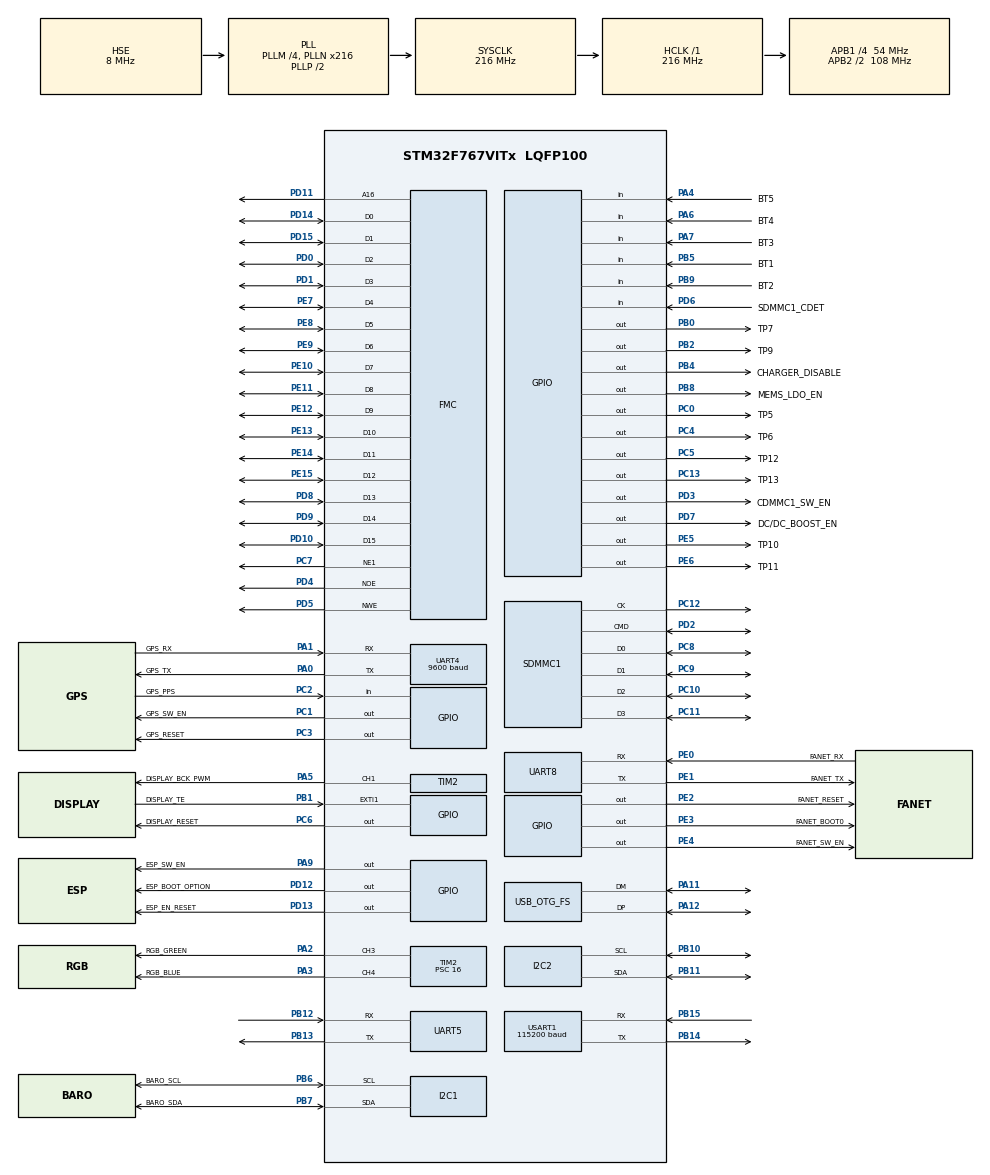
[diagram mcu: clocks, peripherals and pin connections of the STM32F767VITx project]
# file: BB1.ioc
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CORTEX_M7.ART_ACCLERATOR_ENABLE=0
CORTEX_M7.CPU_DCache=Disabled
CORTEX_M7.CPU_ICache=Disabled
CORTEX_M7.FlashInterface=AXI_Enabled
CORTEX_M7.PREFETCH_ENABLE=0
DMA2D.AlphaModeBackground=DMA2D_REPLACE_ALPHA
DMA2D.AlphaModeForeground=DMA2D_REPLACE_ALPHA
DMA2D.ColorMode=DMA2D_OUTPUT_RGB565
DMA2D.InputAlphaBackground=0xff
DMA2D.InputAlphaForeground=0xff
DMA2D.InputColorModeBackground=DMA2D_INPUT_RGB565
DMA2D.InputColorModeForeground=DMA2D_INPUT_RGB565
DMA2D.Mode=DMA2D_M2M_BLEND
Dma.MEMTOMEM.0.Direction=DMA_MEMORY_TO_MEMORY
Dma.MEMTOMEM.0.FIFOMode=DMA_FIFOMODE_ENABLE
Dma.MEMTOMEM.0.FIFOThreshold=DMA_FIFO_THRESHOLD_FULL
Dma.MEMTOMEM.0.Instance=DMA2_Stream0
Dma.MEMTOMEM.0.MemBurst=DMA_MBURST_SINGLE
Dma.MEMTOMEM.0.MemDataAlignment=DMA_MDATAALIGN_WORD
Dma.MEMTOMEM.0.MemInc=DMA_MINC_DISABLE
Dma.MEMTOMEM.0.Mode=DMA_NORMAL
Dma.MEMTOMEM.0.PeriphBurst=DMA_PBURST_SINGLE
Dma.MEMTOMEM.0.PeriphDataAlignment=DMA_PDATAALIGN_WORD
Dma.MEMTOMEM.0.PeriphInc=DMA_PINC_ENABLE
Dma.MEMTOMEM.0.Priority=DMA_PRIORITY_LOW
Dma.Request0=MEMTOMEM
Dma.Request1=SDMMC1_RX
Dma.Request2=SDMMC1_TX
Dma.Request3=UART4_RX
Dma.Request4=UART8_RX
Dma.Request5=USART1_TX
Dma.SDMMC1_RX.1.Direction=DMA_PERIPH_TO_MEMORY
Dma.SDMMC1_RX.1.FIFOMode=DMA_FIFOMODE_ENABLE
Dma.SDMMC1_RX.1.FIFOThreshold=DMA_FIFO_THRESHOLD_FULL
Dma.SDMMC1_RX.1.Instance=DMA2_Stream3
Dma.SDMMC1_RX.1.MemBurst=DMA_MBURST_INC4
Dma.SDMMC1_RX.1.MemDataAlignment=DMA_MDATAALIGN_WORD
Dma.SDMMC1_RX.1.MemInc=DMA_MINC_ENABLE
Dma.SDMMC1_RX.1.Mode=DMA_PFCTRL
Dma.SDMMC1_RX.1.PeriphBurst=DMA_PBURST_INC4
Dma.SDMMC1_RX.1.PeriphDataAlignment=DMA_PDATAALIGN_WORD
Dma.SDMMC1_RX.1.PeriphInc=DMA_PINC_DISABLE
Dma.SDMMC1_RX.1.Priority=DMA_PRIORITY_MEDIUM
Dma.SDMMC1_TX.2.Direction=DMA_MEMORY_TO_PERIPH
Dma.SDMMC1_TX.2.FIFOMode=DMA_FIFOMODE_ENABLE
Dma.SDMMC1_TX.2.FIFOThreshold=DMA_FIFO_THRESHOLD_FULL
Dma.SDMMC1_TX.2.Instance=DMA2_Stream6
Dma.SDMMC1_TX.2.MemBurst=DMA_MBURST_INC4
Dma.SDMMC1_TX.2.MemDataAlignment=DMA_MDATAALIGN_WORD
Dma.SDMMC1_TX.2.MemInc=DMA_MINC_ENABLE
Dma.SDMMC1_TX.2.Mode=DMA_PFCTRL
Dma.SDMMC1_TX.2.PeriphBurst=DMA_PBURST_INC4
Dma.SDMMC1_TX.2.PeriphDataAlignment=DMA_PDATAALIGN_WORD
Dma.SDMMC1_TX.2.PeriphInc=DMA_PINC_DISABLE
Dma.SDMMC1_TX.2.Priority=DMA_PRIORITY_MEDIUM
Dma.UART4_RX.3.Direction=DMA_PERIPH_TO_MEMORY
Dma.UART4_RX.3.FIFOMode=DMA_FIFOMODE_DISABLE
Dma.UART4_RX.3.Instance=DMA1_Stream2
Dma.UART4_RX.3.MemDataAlignment=DMA_MDATAALIGN_BYTE
Dma.UART4_RX.3.MemInc=DMA_MINC_ENABLE
Dma.UART4_RX.3.Mode=DMA_CIRCULAR
Dma.UART4_RX.3.PeriphDataAlignment=DMA_PDATAALIGN_BYTE
Dma.UART4_RX.3.PeriphInc=DMA_PINC_DISABLE
Dma.UART4_RX.3.Priority=DMA_PRIORITY_LOW
Dma.UART8_RX.4.Direction=DMA_PERIPH_TO_MEMORY
Dma.UART8_RX.4.FIFOMode=DMA_FIFOMODE_DISABLE
Dma.UART8_RX.4.Instance=DMA1_Stream6
Dma.UART8_RX.4.MemDataAlignment=DMA_MDATAALIGN_BYTE
Dma.UART8_RX.4.MemInc=DMA_MINC_ENABLE
Dma.UART8_RX.4.Mode=DMA_CIRCULAR
Dma.UART8_RX.4.PeriphDataAlignment=DMA_PDATAALIGN_BYTE
Dma.UART8_RX.4.PeriphInc=DMA_PINC_DISABLE
Dma.UART8_RX.4.Priority=DMA_PRIORITY_LOW
Dma.USART1_TX.5.Direction=DMA_MEMORY_TO_PERIPH
Dma.USART1_TX.5.FIFOMode=DMA_FIFOMODE_DISABLE
Dma.USART1_TX.5.Instance=DMA2_Stream7
Dma.USART1_TX.5.MemDataAlignment=DMA_MDATAALIGN_BYTE
Dma.USART1_TX.5.MemInc=DMA_MINC_ENABLE
Dma.USART1_TX.5.Mode=DMA_NORMAL
Dma.USART1_TX.5.PeriphDataAlignment=DMA_PDATAALIGN_BYTE
Dma.USART1_TX.5.PeriphInc=DMA_PINC_DISABLE
Dma.USART1_TX.5.Priority=DMA_PRIORITY_MEDIUM
FATFS.BSP.number=1
FATFS._FS_LOCK=20
FATFS._MAX_SS=512
FATFS._USE_MUTEX=1
FATFS0.BSP.STBoard=false
FATFS0.BSP.api=Unknown
FATFS0.BSP.i2caddr=0
FATFS0.BSP.instance=PD6
FATFS0.BSP.ip=GPIO
FATFS0.BSP.mode=Input
FATFS0.BSP.name=Detect_SDIO
FATFS0.BSP.solution=PD6
FMC.AddressSetupTime1=6
FMC.BusTurnAroundDuration1=0
FMC.DataSetupTime1=9
FMC.ExtendedMode1=FMC_EXTENDED_MODE_DISABLE
FMC.MemoryType1=FMC_MEMORY_TYPE_SRAM
FMC.WriteFifo1=FMC_WRITE_FIFO_ENABLE
FREERTOS.HEAP_NUMBER=4
FREERTOS.INCLUDE_vTaskDelete=0
FREERTOS.Queues01=queue_Debug,16,debug_msg_t,0,Static,queueDebugBuffer,queueDebugControlBlock
FREERTOS.Tasks01=System,24,1024,task_System,As weak,NULL,Static,defaultTaskBuffer,defaultTaskControlBlock;GUI,8,1024,task_GUI,As external,NULL,Static,GUIBuffer,GUIControlBlock;Debug,40,512,task_Debug,As external,NULL,Static,DebugBuffer,DebugControlBlock;Test,8,1024,task_Test,As external,NULL,Static,TestBuffer,TestControlBlock;GNSS,8,1024,task_GNSS,As external,NULL,Static,GNSSBuffer,GNSSControlBlock
FREERTOS.configENABLE_BACKWARD_COMPATIBILITY=1
FREERTOS.configENABLE_FPU=1
FREERTOS.configGENERATE_RUN_TIME_STATS=1
FREERTOS.configRECORD_STACK_HIGH_ADDRESS=1
FREERTOS.configUSE_APPLICATION_TASK_TAG=0
FREERTOS.configUSE_NEWLIB_REENTRANT=1
FREERTOS.configUSE_STATS_FORMATTING_FUNCTIONS=1
I2C1.Timing=0x20404768
I2C2.Timing=0x20404768
Mcu.Family=STM32F7
Mcu.Name=STM32F767VITx
Mcu.Package=LQFP100
NVIC.DMA1_Stream2_IRQn=true\:5\:0\:false\:false\:true\:true\:false\:true
NVIC.DMA1_Stream6_IRQn=true\:5\:0\:false\:false\:true\:true\:false\:true
NVIC.DMA2_Stream0_IRQn=true\:5\:0\:false\:false\:true\:true\:true\:true
NVIC.DMA2_Stream3_IRQn=true\:5\:0\:false\:false\:true\:true\:false\:true
NVIC.DMA2_Stream6_IRQn=true\:5\:0\:false\:false\:true\:true\:false\:true
NVIC.DMA2_Stream7_IRQn=true\:5\:0\:false\:false\:true\:true\:false\:true
NVIC.EXTI1_IRQn=true\:5\:0\:false\:false\:true\:true\:true\:true
NVIC.OTG_FS_IRQn=true\:5\:0\:false\:false\:true\:true\:false\:true
NVIC.PriorityGroup=NVIC_PRIORITYGROUP_4
NVIC.SDMMC1_IRQn=true\:5\:0\:false\:false\:true\:true\:true\:true
NVIC.TIM1_UP_TIM10_IRQn=true\:0\:0\:false\:false\:true\:false\:false\:true
NVIC.TIM8_TRG_COM_TIM14_IRQn=true\:5\:0\:false\:false\:true\:true\:true\:true
NVIC.TimeBase=TIM1_UP_TIM10_IRQn
NVIC.TimeBaseIP=TIM1
NVIC.USART1_IRQn=true\:5\:0\:false\:false\:true\:true\:true\:true
PA0/WKUP.GPIO_Label=GPS_TX
PA0/WKUP.Mode=Asynchronous
PA0/WKUP.Signal=UART4_TX
PA1.GPIO_Label=GPS_RX
PA1.Mode=Asynchronous
PA1.Signal=UART4_RX
PA10.Signal=USB_OTG_FS_ID
PA11.Mode=Device_Only
PA11.Signal=USB_OTG_FS_DM
PA12.Mode=Device_Only
PA12.Signal=USB_OTG_FS_DP
PA13.Mode=Trace_Asynchronous_SW
PA13.Signal=SYS_JTMS-SWDIO
PA14.Mode=Trace_Asynchronous_SW
PA14.Signal=SYS_JTCK-SWCLK
PA2.GPIO_Label=RGB_GREEN
PA2.Signal=S_TIM2_CH3
PA3.GPIO_Label=RGB_BLUE
PA3.Signal=S_TIM2_CH4
PA4.GPIO_Label=BT5
PA4.GPIO_Mode=GPIO_MODE_INPUT
PA4.GPIO_PuPd=GPIO_PULLUP
PA4.Signal=GPIO_Input
PA5.GPIO_Label=DISPLAY_BCK_PWM
PA5.Signal=S_TIM2_CH1_ETR
PA6.GPIO_Label=BT4
PA6.GPIO_Mode=GPIO_MODE_INPUT
PA6.GPIO_PuPd=GPIO_PULLUP
PA6.Signal=GPIO_Input
PA7.GPIO_Label=BT3
PA7.GPIO_Mode=GPIO_MODE_INPUT
PA7.GPIO_PuPd=GPIO_PULLUP
PA7.Signal=GPIO_Input
PA9.GPIO_Label=ESP_SW_EN
PA9.Signal=GPIO_Output
PB0.GPIO_Label=TP7
PB0.Signal=GPIO_Output
PB1.GPIO_Label=DISPLAY_TE
PB1.GPIO_ModeDefaultEXTI=GPIO_MODE_IT_RISING
PB1.Signal=GPXTI1
PB10.Mode=I2C
PB10.Signal=I2C2_SCL
PB11.Mode=I2C
PB11.Signal=I2C2_SDA
PB12.Mode=Asynchronous
PB12.Signal=UART5_RX
PB13.Mode=Asynchronous
PB13.Signal=UART5_TX
PB14.Mode=Asynchronous
PB14.Signal=USART1_TX
PB15.GPIO_PuPd=GPIO_PULLUP
PB15.Mode=Asynchronous
PB15.Signal=USART1_RX
PB2.GPIO_Label=TP9
PB2.Signal=GPIO_Output
PB3.Mode=Trace_Asynchronous_SW
PB3.Signal=SYS_JTDO-SWO
PB4.GPIO_Label=CHARGER_DISABLE
PB4.Signal=GPIO_Output
PB5.GPIO_Label=BT1
PB5.GPIO_Mode=GPIO_MODE_INPUT
PB5.GPIO_PuPd=GPIO_PULLUP
PB5.Signal=GPIO_Input
PB6.GPIO_Label=BARO_SCL
PB6.Mode=I2C
PB6.Signal=I2C1_SCL
PB7.GPIO_Label=BARO_SDA
PB7.Mode=I2C
PB7.Signal=I2C1_SDA
PB8.GPIO_Label=MEMS_LDO_EN
PB8.Signal=GPIO_Output
PB9.GPIO_Label=BT2
PB9.GPIO_Mode=GPIO_MODE_INPUT
PB9.GPIO_PuPd=GPIO_PULLUP
PB9.Signal=GPIO_Input
PC0.GPIO_Label=TP5
PC0.Signal=GPIO_Output
PC1.GPIO_Label=GPS_SW_EN
PC1.Signal=GPIO_Output
PC10.Mode=SD_4_bits_Wide_bus
PC10.Signal=SDMMC1_D2
PC11.Mode=SD_4_bits_Wide_bus
PC11.Signal=SDMMC1_D3
PC12.Mode=SD_4_bits_Wide_bus
PC12.Signal=SDMMC1_CK
PC13.GPIO_Label=TP13
PC13.Signal=GPIO_Output
PC14/OSC32_IN.Mode=LSE-External-Oscillator
PC14/OSC32_IN.Signal=RCC_OSC32_IN
PC15/OSC32_OUT.Mode=LSE-External-Oscillator
PC15/OSC32_OUT.Signal=RCC_OSC32_OUT
PC2.GPIO_Label=GPS_PPS
PC2.Signal=GPIO_Input
PC3.GPIO_Label=GPS_RESET
PC3.Signal=GPIO_Output
PC4.GPIO_Label=TP6
PC4.Signal=GPIO_Output
PC5.GPIO_Label=TP12
PC5.Signal=GPIO_Output
PC6.GPIO_Label=DISPLAY_RESET
PC6.Signal=GPIO_Output
PC7.Mode=NorPsramChipSelect1_1
PC7.Signal=FMC_NE1
PC8.Mode=SD_4_bits_Wide_bus
PC8.Signal=SDMMC1_D0
PC9.Mode=SD_4_bits_Wide_bus
PC9.Signal=SDMMC1_D1
PD0.Signal=FMC_D2_DA2
PD1.Signal=FMC_D3_DA3
PD10.Signal=FMC_D15_DA15
PD11.Signal=FMC_A16_CLE
PD12.GPIO_Label=ESP_BOOT_OPTION
PD12.Signal=GPIO_Output
PD13.GPIO_Label=ESP_EN_RESET
PD13.Signal=GPIO_Output
PD14.Signal=FMC_D0_DA0
PD15.Signal=FMC_D1_DA1
PD2.Mode=SD_4_bits_Wide_bus
PD2.Signal=SDMMC1_CMD
PD3.GPIO_Label=CDMMC1_SW_EN
PD3.Signal=GPIO_Output
PD4.Signal=FMC_NOE
PD5.Signal=FMC_NWE
PD6.GPIO_Label=SDMMC1_CDET
PD6.Signal=GPIO_Input
PD7.GPIO_Label=DC/DC_BOOST_EN
PD7.Signal=GPIO_Output
PD8.Signal=FMC_D13_DA13
PD9.Signal=FMC_D14_DA14
PE0.GPIO_Label=FANET_RX
PE0.Mode=Asynchronous
PE0.Signal=UART8_RX
PE1.GPIO_Label=FANET_TX
PE1.Mode=Asynchronous
PE1.Signal=UART8_TX
PE10.Signal=FMC_D7_DA7
PE11.Signal=FMC_D8_DA8
PE12.Signal=FMC_D9_DA9
PE13.Signal=FMC_D10_DA10
PE14.Signal=FMC_D11_DA11
PE15.Signal=FMC_D12_DA12
PE2.GPIO_Label=FANET_RESET
PE2.Signal=GPIO_Output
PE3.GPIO_Label=FANET_BOOT0
PE3.Signal=GPIO_Output
PE4.GPIO_Label=FANET_SW_EN
PE4.Signal=GPIO_Output
PE5.GPIO_Label=TP10
PE5.Signal=GPIO_Output
PE6.GPIO_Label=TP11
PE6.Signal=GPIO_Output
PE7.Signal=FMC_D4_DA4
PE8.Signal=FMC_D5_DA5
PE9.Signal=FMC_D6_DA6
PH0/OSC_IN.Mode=HSE-External-Oscillator
PH0/OSC_IN.Signal=RCC_OSC_IN
PH1/OSC_OUT.Mode=HSE-External-Oscillator
PH1/OSC_OUT.Signal=RCC_OSC_OUT
ProjectManager.HeapSize=0x200
ProjectManager.StackSize=0x400
ProjectManager.TargetToolchain=STM32CubeIDE
RCC.AHBFreq_Value=216000000
RCC.APB1CLKDivider=RCC_HCLK_DIV4
RCC.APB1Freq_Value=54000000
RCC.APB1TimFreq_Value=108000000
RCC.APB2CLKDivider=RCC_HCLK_DIV2
RCC.APB2Freq_Value=108000000
RCC.APB2TimFreq_Value=216000000
RCC.CortexFreq_Value=216000000
RCC.EnbaleCSS=true
RCC.HCLKFreq_Value=216000000
RCC.HSE_VALUE=8000000
RCC.HSI_VALUE=16000000
RCC.PLLM=4
RCC.PLLN=216
RCC.PLLQ=9
RCC.SDMMCClockSelection=RCC_SDMMC1CLKSOURCE_CLK48
RCC.SYSCLKFreq_VALUE=216000000
RCC.SYSCLKSource=RCC_SYSCLKSOURCE_PLLCLK
RCC.USBFreq_Value=48000000
RCC.VCOOutputFreq_Value=432000000
SH.FMC_A16_CLE.0=FMC_A16,A16_1
SH.FMC_D0_DA0.0=FMC_D0,16b-d1
SH.FMC_D10_DA10.0=FMC_D10,16b-d1
SH.FMC_D11_DA11.0=FMC_D11,16b-d1
SH.FMC_D12_DA12.0=FMC_D12,16b-d1
SH.FMC_D13_DA13.0=FMC_D13,16b-d1
SH.FMC_D14_DA14.0=FMC_D14,16b-d1
SH.FMC_D15_DA15.0=FMC_D15,16b-d1
SH.FMC_D1_DA1.0=FMC_D1,16b-d1
SH.FMC_D2_DA2.0=FMC_D2,16b-d1
SH.FMC_D3_DA3.0=FMC_D3,16b-d1
SH.FMC_D4_DA4.0=FMC_D4,16b-d1
SH.FMC_D5_DA5.0=FMC_D5,16b-d1
SH.FMC_D6_DA6.0=FMC_D6,16b-d1
SH.FMC_D7_DA7.0=FMC_D7,16b-d1
SH.FMC_D8_DA8.0=FMC_D8,16b-d1
SH.FMC_D9_DA9.0=FMC_D9,16b-d1
SH.FMC_NOE.0=FMC_NOE,Lcd1
SH.FMC_NWE.0=FMC_NWE,Lcd1
SH.S_TIM2_CH1_ETR.0=TIM2_CH1,PWM Generation1 CH1
SH.S_TIM2_CH3.0=TIM2_CH3,PWM Generation3 CH3
SH.S_TIM2_CH4.0=TIM2_CH4,PWM Generation4 CH4
TIM14.AutoReloadPreload=TIM_AUTORELOAD_PRELOAD_ENABLE
TIM14.ClockDivision=TIM_CLOCKDIVISION_DIV4
TIM14.Period=0xffff
TIM14.Prescaler=65535
TIM2.AutoReloadPreload=TIM_AUTORELOAD_PRELOAD_ENABLE
TIM2.Channel-PWM\ Generation1\ CH1=TIM_CHANNEL_1
TIM2.Channel-PWM\ Generation3\ CH3=TIM_CHANNEL_3
TIM2.Channel-PWM\ Generation4\ CH4=TIM_CHANNEL_4
TIM2.Period=100
TIM2.Prescaler=16
TIM2.Pulse-PWM\ Generation1\ CH1=90
TIM2.Pulse-PWM\ Generation3\ CH3=50
TIM2.Pulse-PWM\ Generation4\ CH4=50
UART4.BaudRate=9600
USART1.BaudRate=115200
USART1.VirtualMode-Asynchronous=VM_ASYNC
USB_DEVICE.CLASS_NAME_FS=CDC
USB_DEVICE.USBD_DEBUG_LEVEL-CDC_FS=0
USB_DEVICE.USBD_LPM_ENABLED-CDC_FS=1
USB_DEVICE.VirtualMode-CDC_FS=Cdc
USB_DEVICE.VirtualModeFS=Cdc_FS
USB_OTG_FS.VirtualMode=Device_Only
VP_DMA2D_VS_DMA2D.Mode=DMA2D_Activate
VP_FATFS_VS_SDIO.Mode=SDIO
VP_FREERTOS_VS_CMSIS_V2.Mode=CMSIS_V2
VP_RTC_VS_RTC_Activate.Mode=RTC_Enabled
VP_SYS_VS_tim1.Mode=TIM1
VP_TIM14_VS_ClockSourceINT.Mode=Enable_Timer
VP_TIM2_VS_ClockSourceINT.Mode=Internal
VP_USB_DEVICE_VS_USB_DEVICE_CDC_FS.Mode=CDC_FS
board=custom

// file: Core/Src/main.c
/* USER CODE BEGIN Header */
/**
  ******************************************************************************
  * @file           : main.c
  * @brief          : Main program body
  ******************************************************************************
  * @attention
  *
  * <h2><center>&copy; Copyright (c) 2020 STMicroelectronics.
  * All rights reserved.</center></h2>
  *
  * This software component is licensed by ST under Ultimate Liberty license
  * SLA0044, the "License"; You may not use this file except in compliance with
  * the License. You may obtain a copy of the License at:
  *                             www.st.com/SLA0044
  *
  ******************************************************************************
  */
/* USER CODE END Header */

#include "main.h"
#include "cmsis_os.h"
#include "dma.h"
#include "dma2d.h"
#include "fatfs.h"
#include "i2c.h"
#include "rtc.h"
#include "sdmmc.h"
#include "tim.h"
#include "usart.h"
#include "usb_device.h"
#include "gpio.h"
#include "fmc.h"

void SystemClock_Config(void);
void MX_FREERTOS_Init(void);

/* USER CODE BEGIN 0 */
#define APP_ADDRESS		0x08020000
/* USER CODE END 0 */

int main(void)
{
  /* USER CODE BEGIN 1 */

  //we are using bootloader
  SCB->VTOR = APP_ADDRESS;
  /* USER CODE END 1 */

  /* MCU Configuration--------------------------------------------------------*/

  /* Reset of all peripherals, Initializes the Flash interface and the Systick. */
  HAL_Init();

  /* Configure the system clock */
  SystemClock_Config();

  /* Initialize all configured peripherals */
  MX_GPIO_Init();
  MX_DMA_Init();
  MX_FMC_Init();
  MX_I2C1_Init();
  MX_I2C2_Init();
  MX_SDMMC1_SD_Init();
  MX_TIM2_Init();
  MX_UART4_Init();
  MX_UART5_Init();
  MX_UART8_Init();
  MX_USART1_UART_Init();
  MX_TIM14_Init();
  MX_DMA2D_Init();
  MX_FATFS_Init();
  MX_RTC_Init();

  /* Init scheduler */
  osKernelInitialize();  /* Call init function for freertos objects (in freertos.c) */
  MX_FREERTOS_Init();
  /* Start scheduler */
  osKernelStart();

  /* We should never get here as control is now taken by the scheduler */
  /* Infinite loop */
  while (1)
  {

  }
}

void SystemClock_Config(void)
{
  RCC_OscInitTypeDef RCC_OscInitStruct = {0};
  RCC_ClkInitTypeDef RCC_ClkInitStruct = {0};
  RCC_PeriphCLKInitTypeDef PeriphClkInitStruct = {0};

  /** Configure LSE Drive Capability
  */
  HAL_PWR_EnableBkUpAccess();
  /** Configure the main internal regulator output voltage
  */
  __HAL_RCC_PWR_CLK_ENABLE();
  __HAL_PWR_VOLTAGESCALING_CONFIG(PWR_REGULATOR_VOLTAGE_SCALE1);
  /** Initializes the CPU, AHB and APB busses clocks
  */
  RCC_OscInitStruct.OscillatorType = RCC_OSCILLATORTYPE_LSI|RCC_OSCILLATORTYPE_HSE;
  RCC_OscInitStruct.HSEState = RCC_HSE_ON;
  RCC_OscInitStruct.LSIState = RCC_LSI_ON;
  RCC_OscInitStruct.PLL.PLLState = RCC_PLL_ON;
  RCC_OscInitStruct.PLL.PLLSource = RCC_PLLSOURCE_HSE;
  RCC_OscInitStruct.PLL.PLLM = 4;
  RCC_OscInitStruct.PLL.PLLN = 216;
  RCC_OscInitStruct.PLL.PLLP = RCC_PLLP_DIV2;
  RCC_OscInitStruct.PLL.PLLQ = 9;
  if (HAL_RCC_OscConfig(&RCC_OscInitStruct) != HAL_OK)
  {
    Error_Handler();
  }
  /** Activate the Over-Drive mode
  */
  if (HAL_PWREx_EnableOverDrive() != HAL_OK)
  {
    Error_Handler();
  }
  /** Initializes the CPU, AHB and APB busses clocks
  */
  RCC_ClkInitStruct.ClockType = RCC_CLOCKTYPE_HCLK|RCC_CLOCKTYPE_SYSCLK
                              |RCC_CLOCKTYPE_PCLK1|RCC_CLOCKTYPE_PCLK2;
  RCC_ClkInitStruct.SYSCLKSource = RCC_SYSCLKSOURCE_PLLCLK;
  RCC_ClkInitStruct.AHBCLKDivider = RCC_SYSCLK_DIV1;
  RCC_ClkInitStruct.APB1CLKDivider = RCC_HCLK_DIV4;
  RCC_ClkInitStruct.APB2CLKDivider = RCC_HCLK_DIV2;

  if (HAL_RCC_ClockConfig(&RCC_ClkInitStruct, FLASH_LATENCY_7) != HAL_OK)
  {
    Error_Handler();
  }
  PeriphClkInitStruct.PeriphClockSelection = RCC_PERIPHCLK_RTC|RCC_PERIPHCLK_USART1
                              |RCC_PERIPHCLK_UART4|RCC_PERIPHCLK_UART5
                              |RCC_PERIPHCLK_UART8|RCC_PERIPHCLK_I2C1
                              |RCC_PERIPHCLK_I2C2|RCC_PERIPHCLK_SDMMC1
                              |RCC_PERIPHCLK_CLK48;
  PeriphClkInitStruct.RTCClockSelection = RCC_RTCCLKSOURCE_LSI;
  PeriphClkInitStruct.Usart1ClockSelection = RCC_USART1CLKSOURCE_PCLK2;
  PeriphClkInitStruct.Uart4ClockSelection = RCC_UART4CLKSOURCE_PCLK1;
  PeriphClkInitStruct.Uart5ClockSelection = RCC_UART5CLKSOURCE_PCLK1;
  PeriphClkInitStruct.Uart8ClockSelection = RCC_UART8CLKSOURCE_PCLK1;
  PeriphClkInitStruct.I2c1ClockSelection = RCC_I2C1CLKSOURCE_PCLK1;
  PeriphClkInitStruct.I2c2ClockSelection = RCC_I2C2CLKSOURCE_PCLK1;
  PeriphClkInitStruct.Clk48ClockSelection = RCC_CLK48SOURCE_PLL;
  PeriphClkInitStruct.Sdmmc1ClockSelection = RCC_SDMMC1CLKSOURCE_CLK48;
  if (HAL_RCCEx_PeriphCLKConfig(&PeriphClkInitStruct) != HAL_OK)
  {
    Error_Handler();
  }
  /** Enables the Clock Security System
  */
  HAL_RCC_EnableCSS();
}

/* USER CODE BEGIN 4 */
extern uint16_t rtos_timer;
/* USER CODE END 4 */

 /**
  * @brief  Period elapsed callback in non blocking mode
  * @note   This function is called  when TIM1 interrupt took place, inside
  * HAL_TIM_IRQHandler(). It makes a direct call to HAL_IncTick() to increment
  * a global variable "uwTick" used as application time base.
  * @param  htim : TIM handle
  * @retval None
  */
void HAL_TIM_PeriodElapsedCallback(TIM_HandleTypeDef *htim)
{
  if (htim->Instance == TIM1) {
    HAL_IncTick();
  }
  /* USER CODE BEGIN Callback 1 */

  if (htim->Instance == TIM14) {
	  rtos_timer++;
  }

  /* USER CODE END Callback 1 */
}

void Error_Handler(void)
{
}

/************************ (C) COPYRIGHT STMicroelectronics *****END OF FILE****/

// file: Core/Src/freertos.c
/* USER CODE BEGIN Header */
/**
  ******************************************************************************
  * File Name          : freertos.c
  * Description        : Code for freertos applications
  ******************************************************************************
  * @attention
  *
  * <h2><center>&copy; Copyright (c) 2020 STMicroelectronics.
  * All rights reserved.</center></h2>
  *
  * This software component is licensed by ST under Ultimate Liberty license
  * SLA0044, the "License"; You may not use this file except in compliance with
  * the License. You may obtain a copy of the License at:
  *                             www.st.com/SLA0044
  *
  ******************************************************************************
  */
/* USER CODE END Header */

#include "FreeRTOS.h"
#include "task.h"
#include "main.h"
#include "cmsis_os.h"

/* USER CODE BEGIN Includes */
#include "../../App/debug.h"
/* USER CODE END Includes */

typedef StaticTask_t osStaticThreadDef_t;
typedef StaticQueue_t osStaticMessageQDef_t;

/* Definitions for System */
osThreadId_t SystemHandle;
uint32_t defaultTaskBuffer[ 1024 ];
osStaticThreadDef_t defaultTaskControlBlock;
const osThreadAttr_t System_attributes = {
  .name = "System",
  .stack_mem = &defaultTaskBuffer[0],
  .stack_size = sizeof(defaultTaskBuffer),
  .cb_mem = &defaultTaskControlBlock,
  .cb_size = sizeof(defaultTaskControlBlock),
  .priority = (osPriority_t) osPriorityNormal,
};
/* Definitions for GUI */
osThreadId_t GUIHandle;
uint32_t GUIBuffer[ 1024 ];
osStaticThreadDef_t GUIControlBlock;
const osThreadAttr_t GUI_attributes = {
  .name = "GUI",
  .stack_mem = &GUIBuffer[0],
  .stack_size = sizeof(GUIBuffer),
  .cb_mem = &GUIControlBlock,
  .cb_size = sizeof(GUIControlBlock),
  .priority = (osPriority_t) osPriorityLow,
};
/* Definitions for Debug */
osThreadId_t DebugHandle;
uint32_t DebugBuffer[ 512 ];
osStaticThreadDef_t DebugControlBlock;
const osThreadAttr_t Debug_attributes = {
  .name = "Debug",
  .stack_mem = &DebugBuffer[0],
  .stack_size = sizeof(DebugBuffer),
  .cb_mem = &DebugControlBlock,
  .cb_size = sizeof(DebugControlBlock),
  .priority = (osPriority_t) osPriorityHigh,
};
/* Definitions for Test */
osThreadId_t TestHandle;
uint32_t TestBuffer[ 1024 ];
osStaticThreadDef_t TestControlBlock;
const osThreadAttr_t Test_attributes = {
  .name = "Test",
  .stack_mem = &TestBuffer[0],
  .stack_size = sizeof(TestBuffer),
  .cb_mem = &TestControlBlock,
  .cb_size = sizeof(TestControlBlock),
  .priority = (osPriority_t) osPriorityLow,
};
/* Definitions for GNSS */
osThreadId_t GNSSHandle;
uint32_t GNSSBuffer[ 1024 ];
osStaticThreadDef_t GNSSControlBlock;
const osThreadAttr_t GNSS_attributes = {
  .name = "GNSS",
  .stack_mem = &GNSSBuffer[0],
  .stack_size = sizeof(GNSSBuffer),
  .cb_mem = &GNSSControlBlock,
  .cb_size = sizeof(GNSSControlBlock),
  .priority = (osPriority_t) osPriorityLow,
};
/* Definitions for queue_Debug */
osMessageQueueId_t queue_DebugHandle;
uint8_t queueDebugBuffer[ 16 * sizeof( debug_msg_t ) ];
osStaticMessageQDef_t queueDebugControlBlock;
const osMessageQueueAttr_t queue_Debug_attributes = {
  .name = "queue_Debug",
  .cb_mem = &queueDebugControlBlock,
  .cb_size = sizeof(queueDebugControlBlock),
  .mq_mem = &queueDebugBuffer,
  .mq_size = sizeof(queueDebugBuffer)
};

void task_System(void *argument);
extern void task_GUI(void *argument);
extern void task_Debug(void *argument);
extern void task_Test(void *argument);
extern void task_GNSS(void *argument);

extern void MX_USB_DEVICE_Init(void);
void MX_FREERTOS_Init(void); /* (MISRA C 2004 rule 8.1) */

/* Hook prototypes */
void configureTimerForRunTimeStats(void);
unsigned long getRunTimeCounterValue(void);

/* USER CODE BEGIN 1 */
/* Functions needed when configGENERATE_RUN_TIME_STATS is on */

extern TIM_HandleTypeDef htim14;
uint16_t rtos_timer = 0;

void configureTimerForRunTimeStats(void)
{
	HAL_TIM_Base_Start_IT(&htim14);
}

unsigned long getRunTimeCounterValue(void)
{
	uint32_t cnt = (rtos_timer << 16) | __HAL_TIM_GET_COUNTER(&htim14);
	return cnt;
}
/* USER CODE END 1 */

void MX_FREERTOS_Init(void) {

  /* Create the queue(s) */
  /* creation of queue_Debug */
  queue_DebugHandle = osMessageQueueNew (16, sizeof(debug_msg_t), &queue_Debug_attributes);

  /* Create the thread(s) */
  /* creation of System */
  SystemHandle = osThreadNew(task_System, NULL, &System_attributes);

  /* creation of GUI */
  GUIHandle = osThreadNew(task_GUI, NULL, &GUI_attributes);

  /* creation of Debug */
  DebugHandle = osThreadNew(task_Debug, NULL, &Debug_attributes);

  /* creation of Test */
  TestHandle = osThreadNew(task_Test, NULL, &Test_attributes);

  /* creation of GNSS */
  GNSSHandle = osThreadNew(task_GNSS, NULL, &GNSS_attributes);

}

__weak void task_System(void *argument)
{
  /* init code for USB_DEVICE */
  MX_USB_DEVICE_Init();
  for(;;)
  {
    osDelay(1);
  }
}

/************************ (C) COPYRIGHT STMicroelectronics *****END OF FILE****/
